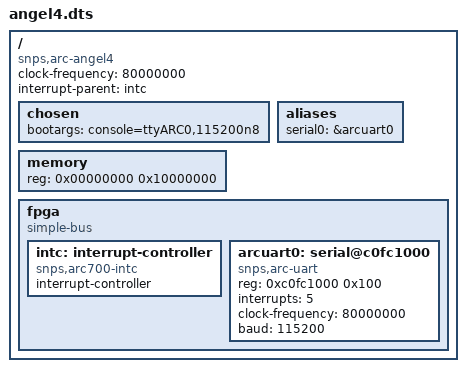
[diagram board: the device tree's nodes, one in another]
/*
 * Copyright (C) 2012 Synopsys, Inc. (www.synopsys.com)
 *
 * This program is free software; you can redistribute it and/or modify
 * it under the terms of the GNU General Public License version 2 as
 * published by the Free Software Foundation.
 */
/dts-v1/;

/include/ "skeleton.dtsi"

/ {
	compatible = "snps,arc-angel4";
	clock-frequency = <80000000>;	/* 80 MHZ */
	#address-cells = <1>;
	#size-cells = <1>;
	interrupt-parent = <&intc>;

	chosen {
		bootargs = "console=ttyARC0,115200n8";
	};

	aliases {
		serial0 = &arcuart0;
	};

	memory {
		device_type = "memory";
		reg = <0x00000000 0x10000000>;	/* 256M */
	};

	fpga {
		compatible = "simple-bus";
		#address-cells = <1>;
		#size-cells = <1>;

		/* child and parent address space 1:1 mapped */
		ranges;

		intc: interrupt-controller {
			compatible = "snps,arc700-intc";
			interrupt-controller;
			#interrupt-cells = <1>;
		};

		arcuart0: serial@c0fc1000 {
			compatible = "snps,arc-uart";
			reg = <0xc0fc1000 0x100>;
			interrupts = <5>;
			clock-frequency = <80000000>;
			baud = <115200>;
			status = "okay";
		};
	};
};
